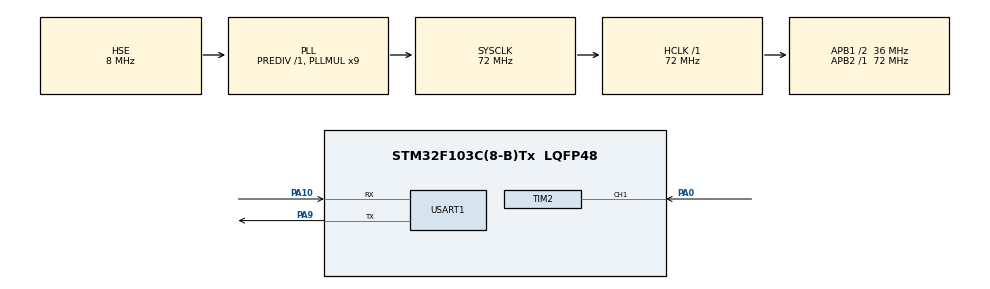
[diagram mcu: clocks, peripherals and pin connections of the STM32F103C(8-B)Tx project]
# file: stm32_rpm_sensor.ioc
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Mcu.Family=STM32F1
Mcu.Name=STM32F103C(8-B)Tx
Mcu.Package=LQFP48
NVIC.PriorityGroup=NVIC_PRIORITYGROUP_4
NVIC.TIM2_IRQn=true\:0\:0\:false\:false\:true\:true\:true\:true
PA0-WKUP.Signal=S_TIM2_CH1_ETR
PA10.Mode=Asynchronous
PA10.Signal=USART1_RX
PA13.Mode=Serial_Wire
PA13.Signal=SYS_JTMS-SWDIO
PA14.Mode=Serial_Wire
PA14.Signal=SYS_JTCK-SWCLK
PA9.Mode=Asynchronous
PA9.Signal=USART1_TX
PD0-OSC_IN.Mode=HSE-External-Oscillator
PD0-OSC_IN.Signal=RCC_OSC_IN
PD1-OSC_OUT.Mode=HSE-External-Oscillator
PD1-OSC_OUT.Signal=RCC_OSC_OUT
ProjectManager.HeapSize=0x200
ProjectManager.StackSize=0x400
ProjectManager.TargetToolchain=Makefile
RCC.AHBFreq_Value=72000000
RCC.APB1CLKDivider=RCC_HCLK_DIV2
RCC.APB1Freq_Value=36000000
RCC.APB1TimFreq_Value=72000000
RCC.APB2Freq_Value=72000000
RCC.APB2TimFreq_Value=72000000
RCC.HCLKFreq_Value=72000000
RCC.PLLMUL=RCC_PLL_MUL9
RCC.PLLSourceVirtual=RCC_PLLSOURCE_HSE
RCC.SYSCLKFreq_VALUE=72000000
RCC.SYSCLKSource=RCC_SYSCLKSOURCE_PLLCLK
RCC.USBFreq_Value=72000000
SH.S_TIM2_CH1_ETR.0=TIM2_CH1,Input_Capture1_from_TI1
TIM2.Channel-Input_Capture1_from_TI1=TIM_CHANNEL_1
USART1.VirtualMode=VM_ASYNC
VP_TIM2_VS_ClockSourceINT.Mode=Internal
board=custom

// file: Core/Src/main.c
/* USER CODE BEGIN Header */
/**
  ******************************************************************************
  * @file           : main.c
  * @brief          : Main program body
  ******************************************************************************
  * @attention
  *
  * Copyright (c) 2025 STMicroelectronics.
  * All rights reserved.
  *
  * This software is licensed under terms that can be found in the LICENSE file
  * in the root directory of this software component.
  * If no LICENSE file comes with this software, it is provided AS-IS.
  *
  ******************************************************************************
  */
/* USER CODE END Header */
#include "main.h"

/* USER CODE BEGIN Includes */
#include "stm32f1xx_it.h"
#include "stdio.h"
#include "string.h"

#define IDLE   0
#define DONE   1
#define F_CLK  72000000UL

volatile uint8_t state = IDLE;
volatile uint8_t message[35] = {'\0'};
volatile uint8_t message2[35] = {'\0'};
volatile uint32_t T1 = 0;
volatile uint32_t T2 = 0;
volatile uint32_t ticks = 0;
volatile uint16_t TIM2_OVC = 0;
volatile uint32_t frequency = 0;
volatile uint32_t rpm = 0;
/* USER CODE END Includes */

TIM_HandleTypeDef htim2;

UART_HandleTypeDef huart1;

void SystemClock_Config(void);
static void MX_GPIO_Init(void);
static void MX_TIM2_Init(void);
static void MX_USART1_UART_Init(void);

int main(void)
{

  /* MCU Configuration--------------------------------------------------------*/

  /* Reset of all peripherals, Initializes the Flash interface and the Systick. */
  HAL_Init();

  /* Configure the system clock */
  SystemClock_Config();

  /* Initialize all configured peripherals */
  MX_GPIO_Init();
  MX_TIM2_Init();
  MX_USART1_UART_Init();
  /* USER CODE BEGIN 2 */
  HAL_TIM_Base_Start_IT(&htim2);
  HAL_TIM_IC_Start_IT(&htim2, TIM_CHANNEL_1);
  /* USER CODE END 2 */

  /* Infinite loop */
  while (1)
  {

    /* USER CODE BEGIN 3 */
    sprintf(message2, "RPM = %lu \n\r", rpm);
    HAL_UART_Transmit(&huart1, message2, sizeof(message2), 100);
    HAL_Delay(1000);
  }
  /* USER CODE END 3 */
}

void HAL_TIM_IC_CaptureCallback(TIM_HandleTypeDef* htim)
{
    if(state == IDLE)
    {
        T1 = TIM2->CCR1;
        TIM2_OVC = 0;
        state = DONE;
    }
    else if(state == DONE)
    {
        T2 = TIM2->CCR1;
        ticks = (T2 + (TIM2_OVC * 65536)) - T1;
        frequency = (uint32_t)(F_CLK/ticks);
        rpm = (frequency * 60 * 2)/1; //RPM = (FRQ * 60 * 2)/POLE
        if(frequency != 0)
        {
           /*
          sprintf(message, "Frequency = %lu Hz\n\r", frequency);
          HAL_UART_Transmit(&huart1, message, sizeof(message), 100);

          sprintf(message2, "RPM = %lu \n\r", rpm);
          HAL_UART_Transmit(&huart1, message2, sizeof(message2), 100);
          */
        }
        state = IDLE;
    }
}

void HAL_TIM_PeriodElapsedCallback(TIM_HandleTypeDef* htim)
{
    TIM2_OVC++;
}

void SystemClock_Config(void)
{
  RCC_OscInitTypeDef RCC_OscInitStruct = {0};
  RCC_ClkInitTypeDef RCC_ClkInitStruct = {0};

  /** Initializes the RCC Oscillators according to the specified parameters
  * in the RCC_OscInitTypeDef structure.
  */
  RCC_OscInitStruct.OscillatorType = RCC_OSCILLATORTYPE_HSE;
  RCC_OscInitStruct.HSEState = RCC_HSE_ON;
  RCC_OscInitStruct.HSEPredivValue = RCC_HSE_PREDIV_DIV1;
  RCC_OscInitStruct.HSIState = RCC_HSI_ON;
  RCC_OscInitStruct.PLL.PLLState = RCC_PLL_ON;
  RCC_OscInitStruct.PLL.PLLSource = RCC_PLLSOURCE_HSE;
  RCC_OscInitStruct.PLL.PLLMUL = RCC_PLL_MUL9;
  if (HAL_RCC_OscConfig(&RCC_OscInitStruct) != HAL_OK)
  {
    Error_Handler();
  }

  /** Initializes the CPU, AHB and APB buses clocks
  */
  RCC_ClkInitStruct.ClockType = RCC_CLOCKTYPE_HCLK|RCC_CLOCKTYPE_SYSCLK
                              |RCC_CLOCKTYPE_PCLK1|RCC_CLOCKTYPE_PCLK2;
  RCC_ClkInitStruct.SYSCLKSource = RCC_SYSCLKSOURCE_PLLCLK;
  RCC_ClkInitStruct.AHBCLKDivider = RCC_SYSCLK_DIV1;
  RCC_ClkInitStruct.APB1CLKDivider = RCC_HCLK_DIV2;
  RCC_ClkInitStruct.APB2CLKDivider = RCC_HCLK_DIV1;

  if (HAL_RCC_ClockConfig(&RCC_ClkInitStruct, FLASH_LATENCY_2) != HAL_OK)
  {
    Error_Handler();
  }
}

static void MX_TIM2_Init(void)
{

  TIM_ClockConfigTypeDef sClockSourceConfig = {0};
  TIM_MasterConfigTypeDef sMasterConfig = {0};
  TIM_IC_InitTypeDef sConfigIC = {0};

  htim2.Instance = TIM2;
  htim2.Init.Prescaler = 0;
  htim2.Init.CounterMode = TIM_COUNTERMODE_UP;
  htim2.Init.Period = 65535;
  htim2.Init.ClockDivision = TIM_CLOCKDIVISION_DIV1;
  htim2.Init.AutoReloadPreload = TIM_AUTORELOAD_PRELOAD_DISABLE;
  if (HAL_TIM_Base_Init(&htim2) != HAL_OK)
  {
    Error_Handler();
  }
  sClockSourceConfig.ClockSource = TIM_CLOCKSOURCE_INTERNAL;
  if (HAL_TIM_ConfigClockSource(&htim2, &sClockSourceConfig) != HAL_OK)
  {
    Error_Handler();
  }
  if (HAL_TIM_IC_Init(&htim2) != HAL_OK)
  {
    Error_Handler();
  }
  sMasterConfig.MasterOutputTrigger = TIM_TRGO_RESET;
  sMasterConfig.MasterSlaveMode = TIM_MASTERSLAVEMODE_DISABLE;
  if (HAL_TIMEx_MasterConfigSynchronization(&htim2, &sMasterConfig) != HAL_OK)
  {
    Error_Handler();
  }
  sConfigIC.ICPolarity = TIM_INPUTCHANNELPOLARITY_RISING;
  sConfigIC.ICSelection = TIM_ICSELECTION_DIRECTTI;
  sConfigIC.ICPrescaler = TIM_ICPSC_DIV1;
  sConfigIC.ICFilter = 0;
  if (HAL_TIM_IC_ConfigChannel(&htim2, &sConfigIC, TIM_CHANNEL_1) != HAL_OK)
  {
    Error_Handler();
  }

}

static void MX_USART1_UART_Init(void)
{

  huart1.Instance = USART1;
  huart1.Init.BaudRate = 115200;
  huart1.Init.WordLength = UART_WORDLENGTH_8B;
  huart1.Init.StopBits = UART_STOPBITS_1;
  huart1.Init.Parity = UART_PARITY_NONE;
  huart1.Init.Mode = UART_MODE_TX_RX;
  huart1.Init.HwFlowCtl = UART_HWCONTROL_NONE;
  huart1.Init.OverSampling = UART_OVERSAMPLING_16;
  if (HAL_UART_Init(&huart1) != HAL_OK)
  {
    Error_Handler();
  }

}

static void MX_GPIO_Init(void)
{

  /* GPIO Ports Clock Enable */
  __HAL_RCC_GPIOD_CLK_ENABLE();
  __HAL_RCC_GPIOA_CLK_ENABLE();

}

void Error_Handler(void)
{
  __disable_irq();
  while (1)
  {
  }
}
